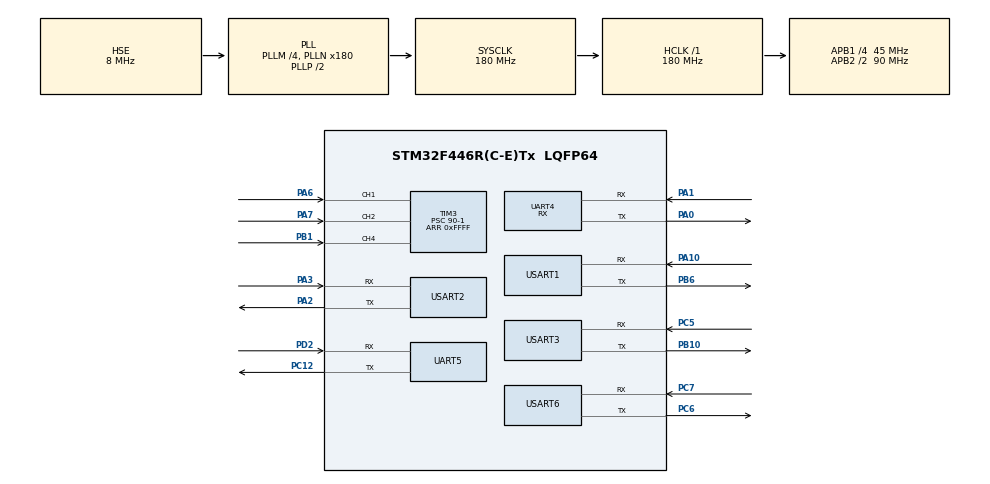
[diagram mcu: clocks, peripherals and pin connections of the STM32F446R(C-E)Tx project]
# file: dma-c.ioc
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Dma.Request0=USART1_RX
Dma.Request1=USART1_TX
Dma.Request10=TIM3_CH4/UP
Dma.Request11=USART2_TX
Dma.Request2=USART3_RX
Dma.Request3=USART3_TX
Dma.Request4=USART6_RX
Dma.Request5=USART6_TX
Dma.Request6=UART5_RX
Dma.Request7=UART5_TX
Dma.Request8=TIM3_CH1/TRIG
Dma.Request9=TIM3_CH2
Dma.TIM3_CH1/TRIG.8.Direction=DMA_PERIPH_TO_MEMORY
Dma.TIM3_CH1/TRIG.8.FIFOMode=DMA_FIFOMODE_DISABLE
Dma.TIM3_CH1/TRIG.8.Instance=DMA1_Stream4
Dma.TIM3_CH1/TRIG.8.MemDataAlignment=DMA_MDATAALIGN_HALFWORD
Dma.TIM3_CH1/TRIG.8.MemInc=DMA_MINC_ENABLE
Dma.TIM3_CH1/TRIG.8.Mode=DMA_CIRCULAR
Dma.TIM3_CH1/TRIG.8.PeriphDataAlignment=DMA_PDATAALIGN_HALFWORD
Dma.TIM3_CH1/TRIG.8.PeriphInc=DMA_PINC_DISABLE
Dma.TIM3_CH1/TRIG.8.Priority=DMA_PRIORITY_LOW
Dma.TIM3_CH2.9.Direction=DMA_PERIPH_TO_MEMORY
Dma.TIM3_CH2.9.FIFOMode=DMA_FIFOMODE_DISABLE
Dma.TIM3_CH2.9.Instance=DMA1_Stream5
Dma.TIM3_CH2.9.MemDataAlignment=DMA_MDATAALIGN_HALFWORD
Dma.TIM3_CH2.9.MemInc=DMA_MINC_ENABLE
Dma.TIM3_CH2.9.Mode=DMA_CIRCULAR
Dma.TIM3_CH2.9.PeriphDataAlignment=DMA_PDATAALIGN_HALFWORD
Dma.TIM3_CH2.9.PeriphInc=DMA_PINC_DISABLE
Dma.TIM3_CH2.9.Priority=DMA_PRIORITY_LOW
Dma.TIM3_CH4/UP.10.Direction=DMA_PERIPH_TO_MEMORY
Dma.TIM3_CH4/UP.10.FIFOMode=DMA_FIFOMODE_DISABLE
Dma.TIM3_CH4/UP.10.Instance=DMA1_Stream2
Dma.TIM3_CH4/UP.10.MemDataAlignment=DMA_MDATAALIGN_HALFWORD
Dma.TIM3_CH4/UP.10.MemInc=DMA_MINC_ENABLE
Dma.TIM3_CH4/UP.10.Mode=DMA_CIRCULAR
Dma.TIM3_CH4/UP.10.PeriphDataAlignment=DMA_PDATAALIGN_HALFWORD
Dma.TIM3_CH4/UP.10.PeriphInc=DMA_PINC_DISABLE
Dma.TIM3_CH4/UP.10.Priority=DMA_PRIORITY_LOW
Dma.UART5_RX.6.Direction=DMA_PERIPH_TO_MEMORY
Dma.UART5_RX.6.FIFOMode=DMA_FIFOMODE_DISABLE
Dma.UART5_RX.6.Instance=DMA1_Stream0
Dma.UART5_RX.6.MemDataAlignment=DMA_MDATAALIGN_BYTE
Dma.UART5_RX.6.MemInc=DMA_MINC_ENABLE
Dma.UART5_RX.6.Mode=DMA_NORMAL
Dma.UART5_RX.6.PeriphDataAlignment=DMA_PDATAALIGN_BYTE
Dma.UART5_RX.6.PeriphInc=DMA_PINC_DISABLE
Dma.UART5_RX.6.Priority=DMA_PRIORITY_LOW
Dma.UART5_TX.7.Direction=DMA_MEMORY_TO_PERIPH
Dma.UART5_TX.7.FIFOMode=DMA_FIFOMODE_DISABLE
Dma.UART5_TX.7.Instance=DMA1_Stream7
Dma.UART5_TX.7.MemDataAlignment=DMA_MDATAALIGN_BYTE
Dma.UART5_TX.7.MemInc=DMA_MINC_ENABLE
Dma.UART5_TX.7.Mode=DMA_NORMAL
Dma.UART5_TX.7.PeriphDataAlignment=DMA_PDATAALIGN_BYTE
Dma.UART5_TX.7.PeriphInc=DMA_PINC_DISABLE
Dma.UART5_TX.7.Priority=DMA_PRIORITY_LOW
Dma.USART1_RX.0.Direction=DMA_PERIPH_TO_MEMORY
Dma.USART1_RX.0.FIFOMode=DMA_FIFOMODE_DISABLE
Dma.USART1_RX.0.Instance=DMA2_Stream2
Dma.USART1_RX.0.MemDataAlignment=DMA_MDATAALIGN_BYTE
Dma.USART1_RX.0.MemInc=DMA_MINC_ENABLE
Dma.USART1_RX.0.Mode=DMA_NORMAL
Dma.USART1_RX.0.PeriphDataAlignment=DMA_PDATAALIGN_BYTE
Dma.USART1_RX.0.PeriphInc=DMA_PINC_DISABLE
Dma.USART1_RX.0.Priority=DMA_PRIORITY_LOW
Dma.USART1_TX.1.Direction=DMA_MEMORY_TO_PERIPH
Dma.USART1_TX.1.FIFOMode=DMA_FIFOMODE_DISABLE
Dma.USART1_TX.1.Instance=DMA2_Stream7
Dma.USART1_TX.1.MemDataAlignment=DMA_MDATAALIGN_BYTE
Dma.USART1_TX.1.MemInc=DMA_MINC_ENABLE
Dma.USART1_TX.1.Mode=DMA_NORMAL
Dma.USART1_TX.1.PeriphDataAlignment=DMA_PDATAALIGN_BYTE
Dma.USART1_TX.1.PeriphInc=DMA_PINC_DISABLE
Dma.USART1_TX.1.Priority=DMA_PRIORITY_LOW
Dma.USART2_TX.11.Direction=DMA_MEMORY_TO_PERIPH
Dma.USART2_TX.11.FIFOMode=DMA_FIFOMODE_DISABLE
Dma.USART2_TX.11.Instance=DMA1_Stream6
Dma.USART2_TX.11.MemDataAlignment=DMA_MDATAALIGN_BYTE
Dma.USART2_TX.11.MemInc=DMA_MINC_ENABLE
Dma.USART2_TX.11.Mode=DMA_NORMAL
Dma.USART2_TX.11.PeriphDataAlignment=DMA_PDATAALIGN_BYTE
Dma.USART2_TX.11.PeriphInc=DMA_PINC_DISABLE
Dma.USART2_TX.11.Priority=DMA_PRIORITY_LOW
Dma.USART3_RX.2.Direction=DMA_PERIPH_TO_MEMORY
Dma.USART3_RX.2.FIFOMode=DMA_FIFOMODE_DISABLE
Dma.USART3_RX.2.Instance=DMA1_Stream1
Dma.USART3_RX.2.MemDataAlignment=DMA_MDATAALIGN_BYTE
Dma.USART3_RX.2.MemInc=DMA_MINC_ENABLE
Dma.USART3_RX.2.Mode=DMA_NORMAL
Dma.USART3_RX.2.PeriphDataAlignment=DMA_PDATAALIGN_BYTE
Dma.USART3_RX.2.PeriphInc=DMA_PINC_DISABLE
Dma.USART3_RX.2.Priority=DMA_PRIORITY_LOW
Dma.USART3_TX.3.Direction=DMA_MEMORY_TO_PERIPH
Dma.USART3_TX.3.FIFOMode=DMA_FIFOMODE_DISABLE
Dma.USART3_TX.3.Instance=DMA1_Stream3
Dma.USART3_TX.3.MemDataAlignment=DMA_MDATAALIGN_BYTE
Dma.USART3_TX.3.MemInc=DMA_MINC_ENABLE
Dma.USART3_TX.3.Mode=DMA_NORMAL
Dma.USART3_TX.3.PeriphDataAlignment=DMA_PDATAALIGN_BYTE
Dma.USART3_TX.3.PeriphInc=DMA_PINC_DISABLE
Dma.USART3_TX.3.Priority=DMA_PRIORITY_LOW
Dma.USART6_RX.4.Direction=DMA_PERIPH_TO_MEMORY
Dma.USART6_RX.4.FIFOMode=DMA_FIFOMODE_DISABLE
Dma.USART6_RX.4.Instance=DMA2_Stream1
Dma.USART6_RX.4.MemDataAlignment=DMA_MDATAALIGN_BYTE
Dma.USART6_RX.4.MemInc=DMA_MINC_ENABLE
Dma.USART6_RX.4.Mode=DMA_NORMAL
Dma.USART6_RX.4.PeriphDataAlignment=DMA_PDATAALIGN_BYTE
Dma.USART6_RX.4.PeriphInc=DMA_PINC_DISABLE
Dma.USART6_RX.4.Priority=DMA_PRIORITY_LOW
Dma.USART6_TX.5.Direction=DMA_MEMORY_TO_PERIPH
Dma.USART6_TX.5.FIFOMode=DMA_FIFOMODE_DISABLE
Dma.USART6_TX.5.Instance=DMA2_Stream6
Dma.USART6_TX.5.MemDataAlignment=DMA_MDATAALIGN_BYTE
Dma.USART6_TX.5.MemInc=DMA_MINC_ENABLE
Dma.USART6_TX.5.Mode=DMA_NORMAL
Dma.USART6_TX.5.PeriphDataAlignment=DMA_PDATAALIGN_BYTE
Dma.USART6_TX.5.PeriphInc=DMA_PINC_DISABLE
Dma.USART6_TX.5.Priority=DMA_PRIORITY_LOW
Mcu.Family=STM32F4
Mcu.Name=STM32F446R(C-E)Tx
Mcu.Package=LQFP64
NVIC.DMA1_Stream0_IRQn=true\:0\:0\:false\:false\:true\:false\:true
NVIC.DMA1_Stream1_IRQn=true\:0\:0\:false\:false\:true\:false\:true
NVIC.DMA1_Stream2_IRQn=true\:0\:0\:false\:false\:true\:false\:true
NVIC.DMA1_Stream3_IRQn=true\:0\:0\:false\:false\:true\:false\:true
NVIC.DMA1_Stream4_IRQn=true\:0\:0\:false\:false\:true\:false\:true
NVIC.DMA1_Stream5_IRQn=true\:0\:0\:false\:false\:true\:false\:true
NVIC.DMA1_Stream6_IRQn=true\:0\:0\:false\:false\:true\:false\:true
NVIC.DMA1_Stream7_IRQn=true\:0\:0\:false\:false\:true\:false\:true
NVIC.DMA2_Stream1_IRQn=true\:0\:0\:false\:false\:true\:false\:true
NVIC.DMA2_Stream2_IRQn=true\:0\:0\:false\:false\:true\:false\:true
NVIC.DMA2_Stream6_IRQn=true\:0\:0\:false\:false\:true\:false\:true
NVIC.DMA2_Stream7_IRQn=true\:0\:0\:false\:false\:true\:false\:true
NVIC.PriorityGroup=NVIC_PRIORITYGROUP_0
PA0-WKUP.Mode=Asynchronous
PA0-WKUP.Signal=UART4_TX
PA1.Mode=Asynchronous
PA1.Signal=UART4_RX
PA10.Mode=Asynchronous
PA10.Signal=USART1_RX
PA13.GPIO_Label=TMS
PA13.Signal=SYS_JTMS-SWDIO
PA14.GPIO_Label=TCK
PA14.Signal=SYS_JTCK-SWCLK
PA2.Mode=Asynchronous
PA2.Signal=USART2_TX
PA3.Mode=Asynchronous
PA3.Signal=USART2_RX
PA6.Signal=S_TIM3_CH1
PA7.Signal=S_TIM3_CH2
PB1.Signal=S_TIM3_CH4
PB10.Mode=Asynchronous
PB10.Signal=USART3_TX
PB3.GPIO_Label=SWO
PB3.Signal=SYS_JTDO-SWO
PB6.Mode=Asynchronous
PB6.Signal=USART1_TX
PC12.Mode=Asynchronous
PC12.Signal=UART5_TX
PC14-OSC32_IN.Signal=RCC_OSC32_IN
PC15-OSC32_OUT.Signal=RCC_OSC32_OUT
PC5.Mode=Asynchronous
PC5.Signal=USART3_RX
PC6.Mode=Asynchronous
PC6.Signal=USART6_TX
PC7.Mode=Asynchronous
PC7.Signal=USART6_RX
PD2.Mode=Asynchronous
PD2.Signal=UART5_RX
PH0-OSC_IN.Mode=HSE-External-Oscillator
PH0-OSC_IN.Signal=RCC_OSC_IN
PH1-OSC_OUT.Mode=HSE-External-Oscillator
PH1-OSC_OUT.Signal=RCC_OSC_OUT
ProjectManager.HeapSize=0x200
ProjectManager.StackSize=0x400
ProjectManager.TargetToolchain=STM32CubeIDE
RCC.AHBFreq_Value=180000000
RCC.APB1CLKDivider=RCC_HCLK_DIV4
RCC.APB1Freq_Value=45000000
RCC.APB1TimFreq_Value=90000000
RCC.APB2CLKDivider=RCC_HCLK_DIV2
RCC.APB2Freq_Value=90000000
RCC.APB2TimFreq_Value=180000000
RCC.CortexFreq_Value=180000000
RCC.FLatency-AdvancedSettings=FLASH_LATENCY_5
RCC.HCLKFreq_Value=180000000
RCC.HSE_VALUE=8000000
RCC.HSI_VALUE=16000000
RCC.LSE_VALUE=32768
RCC.PLLM=4
RCC.PLLN=180
RCC.PLLSourceVirtual=RCC_PLLSOURCE_HSE
RCC.SYSCLKFreq_VALUE=180000000
RCC.SYSCLKSource=RCC_SYSCLKSOURCE_PLLCLK
RCC.USBFreq_Value=180000000
RCC.VCOOutputFreq_Value=360000000
SH.S_TIM3_CH1.0=TIM3_CH1,Input_Capture1_from_TI1
SH.S_TIM3_CH2.0=TIM3_CH2,Input_Capture2_from_TI2
SH.S_TIM3_CH4.0=TIM3_CH4,Input_Capture4_from_TI4
TIM3.Channel-Input_Capture1_from_TI1=TIM_CHANNEL_1
TIM3.Channel-Input_Capture2_from_TI2=TIM_CHANNEL_2
TIM3.Channel-Input_Capture4_from_TI4=TIM_CHANNEL_4
TIM3.ICPolarity_CH1=TIM_INPUTCHANNELPOLARITY_BOTHEDGE
TIM3.ICPolarity_CH2=TIM_INPUTCHANNELPOLARITY_BOTHEDGE
TIM3.ICPolarity_CH4=TIM_INPUTCHANNELPOLARITY_BOTHEDGE
TIM3.Period=0xFFFF
TIM3.Prescaler=90-1
UART4.Mode=MODE_RX
UART4.VirtualMode=Asynchronous
UART5.VirtualMode=Asynchronous
USART1.VirtualMode=VM_ASYNC
USART2.VirtualMode=VM_ASYNC
USART3.VirtualMode=VM_ASYNC
USART6.VirtualMode=VM_ASYNC
board=NUCLEO-F446RE

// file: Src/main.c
/* USER CODE BEGIN Header */
/**
  ******************************************************************************
  * @file           : main.c
  * @brief          : Main program body
  ******************************************************************************
  * @attention
  *
  * <h2><center>&copy; Copyright (c) 2020 STMicroelectronics.
  * All rights reserved.</center></h2>
  *
  * This software component is licensed by ST under BSD 3-Clause license,
  * the "License"; You may not use this file except in compliance with the
  * License. You may obtain a copy of the License at:
  *                        opensource.org/licenses/BSD-3-Clause
  *
  ******************************************************************************
  */
/* USER CODE END Header */

#include "main.h"
#include "dma.h"
#include "tim.h"
#include "usart.h"
#include "gpio.h"

/* USER CODE BEGIN Includes */
#include "dma.h"
/* USER CODE END Includes */

void SystemClock_Config(void);

int main(void)
{

  /* MCU Configuration--------------------------------------------------------*/

  /* Reset of all peripherals, Initializes the Flash interface and the Systick. */
  HAL_Init();

  /* Configure the system clock */
  SystemClock_Config();

  /* Initialize all configured peripherals */
  MX_GPIO_Init();
  MX_DMA_Init();
  MX_USART2_UART_Init();
  MX_TIM3_Init();
  MX_UART4_Init();
  MX_UART5_Init();
  MX_USART1_UART_Init();
  MX_USART3_UART_Init();
  MX_USART6_UART_Init();

  /* Infinite loop */
  while (1)
  {

  }
}

void SystemClock_Config(void)
{
  RCC_OscInitTypeDef RCC_OscInitStruct = {0};
  RCC_ClkInitTypeDef RCC_ClkInitStruct = {0};

  /** Configure the main internal regulator output voltage
  */
  __HAL_RCC_PWR_CLK_ENABLE();
  __HAL_PWR_VOLTAGESCALING_CONFIG(PWR_REGULATOR_VOLTAGE_SCALE1);
  /** Initializes the CPU, AHB and APB busses clocks
  */
  RCC_OscInitStruct.OscillatorType = RCC_OSCILLATORTYPE_HSE;
  RCC_OscInitStruct.HSEState = RCC_HSE_ON;
  RCC_OscInitStruct.PLL.PLLState = RCC_PLL_ON;
  RCC_OscInitStruct.PLL.PLLSource = RCC_PLLSOURCE_HSE;
  RCC_OscInitStruct.PLL.PLLM = 4;
  RCC_OscInitStruct.PLL.PLLN = 180;
  RCC_OscInitStruct.PLL.PLLP = RCC_PLLP_DIV2;
  RCC_OscInitStruct.PLL.PLLQ = 2;
  RCC_OscInitStruct.PLL.PLLR = 2;
  if (HAL_RCC_OscConfig(&RCC_OscInitStruct) != HAL_OK)
  {
    Error_Handler();
  }
  /** Activate the Over-Drive mode
  */
  if (HAL_PWREx_EnableOverDrive() != HAL_OK)
  {
    Error_Handler();
  }
  /** Initializes the CPU, AHB and APB busses clocks
  */
  RCC_ClkInitStruct.ClockType = RCC_CLOCKTYPE_HCLK|RCC_CLOCKTYPE_SYSCLK
                              |RCC_CLOCKTYPE_PCLK1|RCC_CLOCKTYPE_PCLK2;
  RCC_ClkInitStruct.SYSCLKSource = RCC_SYSCLKSOURCE_PLLCLK;
  RCC_ClkInitStruct.AHBCLKDivider = RCC_SYSCLK_DIV1;
  RCC_ClkInitStruct.APB1CLKDivider = RCC_HCLK_DIV4;
  RCC_ClkInitStruct.APB2CLKDivider = RCC_HCLK_DIV2;

  if (HAL_RCC_ClockConfig(&RCC_ClkInitStruct, FLASH_LATENCY_5) != HAL_OK)
  {
    Error_Handler();
  }
}

void Error_Handler(void)
{
}

/************************ (C) COPYRIGHT STMicroelectronics *****END OF FILE****/
